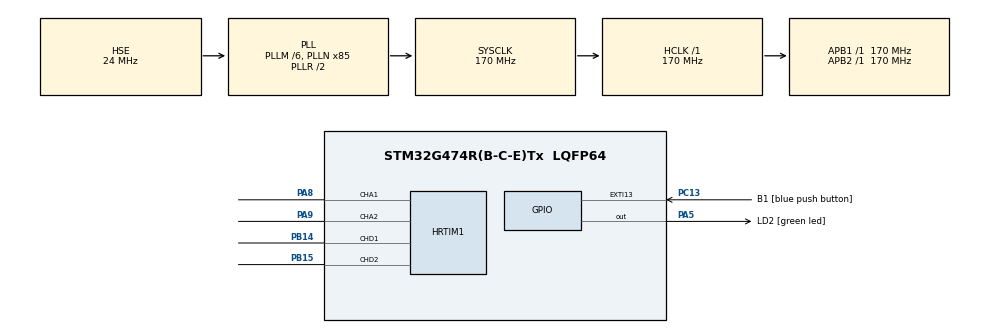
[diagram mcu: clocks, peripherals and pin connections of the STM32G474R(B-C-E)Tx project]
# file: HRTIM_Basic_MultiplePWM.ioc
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HRTIM1.ADCTrigger_Id1=__NULL
HRTIM1.ADCTrigger_Id10=__NULL
HRTIM1.ADCTrigger_Id2=__NULL
HRTIM1.ADCTrigger_Id3=__NULL
HRTIM1.ADCTrigger_Id4=__NULL
HRTIM1.ADCTrigger_Id5=__NULL
HRTIM1.ADCTrigger_Id6=__NULL
HRTIM1.ADCTrigger_Id7=__NULL
HRTIM1.ADCTrigger_Id8=__NULL
HRTIM1.ADCTrigger_Id9=__NULL
HRTIM1.AutoDelayedMode2-Output_TA1TA2=HRTIM_AUTODELAYEDMODE_REGULAR
HRTIM1.AutoDelayedMode2-Output_TD1TD2=HRTIM_AUTODELAYEDMODE_REGULAR
HRTIM1.BurstDMAconfig-Output_TA1TA2=__NULL
HRTIM1.BurstDMAconfig-Output_TD1TD2=__NULL
HRTIM1.BurstMode-Output_TA1TA2=HRTIM_TIMERBURSTMODE_MAINTAINCLOCK
HRTIM1.BurstMode-Output_TD1TD2=HRTIM_TIMERBURSTMODE_MAINTAINCLOCK
HRTIM1.BurstModeEntryDelayed1-Output_TA1TA2=HRTIM_OUTPUTBURSTMODEENTRY_REGULAR
HRTIM1.BurstModeEntryDelayed1-Output_TD1TD2=HRTIM_OUTPUTBURSTMODEENTRY_REGULAR
HRTIM1.BurstModeEntryDelayed2-Output_TA1TA2=HRTIM_OUTPUTBURSTMODEENTRY_REGULAR
HRTIM1.BurstModeEntryDelayed2-Output_TD1TD2=HRTIM_OUTPUTBURSTMODEENTRY_REGULAR
HRTIM1.CaptureUnit1-Output_TA1TA2=__NULL
HRTIM1.CaptureUnit1-Output_TD1TD2=__NULL
HRTIM1.CaptureUnit2-Output_TA1TA2=__NULL
HRTIM1.CaptureUnit2-Output_TD1TD2=__NULL
HRTIM1.ChopperModeEnable1-Output_TA1TA2=HRTIM_OUTPUTCHOPPERMODE_DISABLED
HRTIM1.ChopperModeEnable1-Output_TD1TD2=HRTIM_OUTPUTCHOPPERMODE_DISABLED
HRTIM1.ChopperModeEnable2-Output_TA1TA2=HRTIM_OUTPUTCHOPPERMODE_DISABLED
HRTIM1.ChopperModeEnable2-Output_TD1TD2=HRTIM_OUTPUTCHOPPERMODE_DISABLED
HRTIM1.ChopperModeconfig-Output_TA1TA2=__NULL
HRTIM1.ChopperModeconfig-Output_TD1TD2=__NULL
HRTIM1.CompareUnit1-Output_TA1TA2=HRTIM_COMPAREUNIT_1
HRTIM1.CompareUnit1-Output_TD1TD2=HRTIM_COMPAREUNIT_1
HRTIM1.CompareUnit2-Output_TA1TA2=HRTIM_COMPAREUNIT_2
HRTIM1.CompareUnit2-Output_TD1TD2=HRTIM_COMPAREUNIT_2
HRTIM1.CompareUnit3-Output_TA1TA2=HRTIM_COMPAREUNIT_3
HRTIM1.CompareUnit3-Output_TD1TD2=__NULL
HRTIM1.CompareUnit4-Output_TA1TA2=__NULL
HRTIM1.CompareUnit4-Output_TD1TD2=__NULL
HRTIM1.CompareValue1-Output_TA1TA2=TIMA_PERIOD/4
HRTIM1.CompareValue1-Output_TD1TD2=TIMD_PERIOD/4
HRTIM1.CompareValue2-Output_TA1TA2=TIMA_PERIOD/2
HRTIM1.CompareValue2-Output_TD1TD2=(3*TIMD_PERIOD)/4
HRTIM1.CompareValue3-Output_TA1TA2=(3*TIMA_PERIOD)/4
HRTIM1.Configuration_TA=Waveform
HRTIM1.Configuration_TD=Waveform
HRTIM1.DACSynchro-Output_TA1TA2=HRTIM_DACSYNC_NONE
HRTIM1.DACSynchro-Output_TD1TD2=HRTIM_DACSYNC_NONE
HRTIM1.DeadTimeInsertion-Output_TA1TA2=HRTIM_TIMDEADTIMEINSERTION_DISABLED
HRTIM1.DeadTimeInsertion-Output_TD1TD2=HRTIM_TIMDEADTIMEINSERTION_DISABLED
HRTIM1.Deadtimeconfig-Output_TA1TA2=__NULL
HRTIM1.Deadtimeconfig-Output_TD1TD2=__NULL
HRTIM1.DelayedProtectionMode-Output_TA1TA2=HRTIM_TIMER_A_B_C_DELAYEDPROTECTION_DISABLED
HRTIM1.DelayedProtectionMode-Output_TD1TD2=HRTIM_TIMER_D_E_DELAYEDPROTECTION_DISABLED
HRTIM1.DualChannelDacEnableFake_TA-Output_TA1TA2=HRTIM_TIMER_DCDE_DISABLED
HRTIM1.DualChannelDacEnableFake_TD-Output_TD1TD2=HRTIM_TIMER_DCDE_DISABLED
HRTIM1.Enable=HRTIM_BURSTMODECTL_DISABLED
HRTIM1.Event1-Output_TA1TA2=__NULL
HRTIM1.Event1-Output_TD1TD2=__NULL
HRTIM1.Event10-Output_TA1TA2=__NULL
HRTIM1.Event10-Output_TD1TD2=__NULL
HRTIM1.Event2-Output_TA1TA2=__NULL
HRTIM1.Event2-Output_TD1TD2=__NULL
HRTIM1.Event3-Output_TA1TA2=__NULL
HRTIM1.Event3-Output_TD1TD2=__NULL
HRTIM1.Event4-Output_TA1TA2=__NULL
HRTIM1.Event4-Output_TD1TD2=__NULL
HRTIM1.Event5-Output_TA1TA2=__NULL
HRTIM1.Event5-Output_TD1TD2=__NULL
HRTIM1.Event6-Output_TA1TA2=__NULL
HRTIM1.Event6-Output_TD1TD2=__NULL
HRTIM1.Event7-Output_TA1TA2=__NULL
HRTIM1.Event7-Output_TD1TD2=__NULL
HRTIM1.Event8-Output_TA1TA2=__NULL
HRTIM1.Event8-Output_TD1TD2=__NULL
HRTIM1.Event9-Output_TA1TA2=__NULL
HRTIM1.Event9-Output_TD1TD2=__NULL
HRTIM1.EventEnableA-Output_TA1TA2=__NULL
HRTIM1.EventEnableA-Output_TD1TD2=__NULL
HRTIM1.Event_EEV1=__NULL
HRTIM1.Event_EEV10=__NULL
HRTIM1.Event_EEV2=__NULL
HRTIM1.Event_EEV3=__NULL
HRTIM1.Event_EEV4=__NULL
HRTIM1.Event_EEV5=__NULL
HRTIM1.Event_EEV6=__NULL
HRTIM1.Event_EEV7=__NULL
HRTIM1.Event_EEV8=__NULL
HRTIM1.Event_EEV9=__NULL
HRTIM1.FaultLevel1-Output_TA1TA2=HRTIM_OUTPUTFAULTLEVEL_NONE
HRTIM1.FaultLevel1-Output_TD1TD2=HRTIM_OUTPUTFAULTLEVEL_NONE
HRTIM1.FaultLevel2-Output_TA1TA2=HRTIM_OUTPUTFAULTLEVEL_NONE
HRTIM1.FaultLevel2-Output_TD1TD2=HRTIM_OUTPUTFAULTLEVEL_NONE
HRTIM1.FaultLock-Output_TA1TA2=HRTIM_TIMFAULTLOCK_READWRITE
HRTIM1.FaultLock-Output_TD1TD2=HRTIM_TIMFAULTLOCK_READWRITE
HRTIM1.Fault_Line1=__NULL
HRTIM1.Fault_Line2=__NULL
HRTIM1.Fault_Line3=__NULL
HRTIM1.Fault_Line4=__NULL
HRTIM1.Fault_Line5=__NULL
HRTIM1.Fault_Line6=__NULL
HRTIM1.GreaterCMP1_TA=HRTIM_TIMERGTCMP1_GREATER
HRTIM1.GreaterCMP1_TD=HRTIM_TIMERGTCMP1_EQUAL
HRTIM1.GreaterCMP3_TA=HRTIM_TIMERGTCMP3_EQUAL
HRTIM1.HRTIMInterruptResquests1=HRTIM_IT_NONE
HRTIM1.HRTIMInterruptResquests2=HRTIM_IT_NONE
HRTIM1.HRTIMInterruptResquests3=HRTIM_IT_NONE
HRTIM1.HRTIMInterruptResquests4=HRTIM_IT_NONE
HRTIM1.HRTIMInterruptResquests5=HRTIM_IT_NONE
HRTIM1.HRTIMInterruptResquests6=HRTIM_IT_NONE
HRTIM1.HRTIMInterruptResquests7=HRTIM_IT_NONE
HRTIM1.HRTIMInterruptResquests8=HRTIM_IT_NONE
HRTIM1.HRTIMInterruptResquests9=HRTIM_IT_NONE
HRTIM1.IdleLevel1-Output_TA1TA2=HRTIM_OUTPUTIDLELEVEL_INACTIVE
HRTIM1.IdleLevel1-Output_TD1TD2=HRTIM_OUTPUTIDLELEVEL_INACTIVE
HRTIM1.IdleLevel2-Output_TA1TA2=HRTIM_OUTPUTIDLELEVEL_INACTIVE
HRTIM1.IdleLevel2-Output_TD1TD2=HRTIM_OUTPUTIDLELEVEL_INACTIVE
HRTIM1.IdleMode1-Output_TA1TA2=HRTIM_OUTPUTIDLEMODE_NONE
HRTIM1.IdleMode1-Output_TD1TD2=HRTIM_OUTPUTIDLEMODE_NONE
HRTIM1.IdleMode2-Output_TA1TA2=HRTIM_OUTPUTIDLEMODE_NONE
HRTIM1.IdleMode2-Output_TD1TD2=HRTIM_OUTPUTIDLEMODE_NONE
HRTIM1.InterleavedMode-Output_TA1TA2=HRTIM_INTERLEAVED_MODE_DISABLED
HRTIM1.InterleavedMode-Output_TD1TD2=HRTIM_INTERLEAVED_MODE_DISABLED
HRTIM1.ModeTimeBase-Output_TA1TA2=HRTIM_MODE_CONTINUOUS
HRTIM1.ModeTimeBase-Output_TD1TD2=HRTIM_MODE_CONTINUOUS
HRTIM1.NumberDMARequests_TA=0
HRTIM1.NumberDMARequests_TD=0
HRTIM1.NumberFaultEnable-Output_TA1TA2=0
HRTIM1.NumberFaultEnable-Output_TD1TD2=0
HRTIM1.NumberInterruptRequests-Output_TA1TA2=0
HRTIM1.NumberInterruptRequests-Output_TD1TD2=0
HRTIM1.NumberResetSource1-Output_TA1TA2=1
HRTIM1.NumberResetSource1-Output_TD1TD2=1
HRTIM1.NumberResetSource2_TA=1
HRTIM1.NumberResetSource2_TD=1
HRTIM1.NumberResetTrigger-Output_TA1TA2=0
HRTIM1.NumberResetTrigger-Output_TD1TD2=0
HRTIM1.NumberSetSource1-Output_TA1TA2=1
HRTIM1.NumberSetSource1-Output_TD1TD2=1
HRTIM1.NumberSetSource2_TA=1
HRTIM1.NumberSetSource2_TD=1
HRTIM1.NumberUpdateTrigger-Output_TA1TA2=0
HRTIM1.NumberUpdateTrigger-Output_TD1TD2=0
HRTIM1.Output1-Output_TA1TA2=HRTIM_OUTPUT_TA1
HRTIM1.Output1-Output_TD1TD2=HRTIM_OUTPUT_TD1
HRTIM1.Output2-Output_TA1TA2=HRTIM_OUTPUT_TA2
HRTIM1.Output2-Output_TD1TD2=HRTIM_OUTPUT_TD2
HRTIM1.Periode_TA=TIMA_PERIOD
HRTIM1.Periode_TD=TIMD_PERIOD
HRTIM1.Polarity1-Output_TA1TA2=HRTIM_OUTPUTPOLARITY_HIGH
HRTIM1.Polarity1-Output_TD1TD2=HRTIM_OUTPUTPOLARITY_HIGH
HRTIM1.Polarity2-Output_TA1TA2=HRTIM_OUTPUTPOLARITY_HIGH
HRTIM1.Polarity2-Output_TD1TD2=HRTIM_OUTPUTPOLARITY_HIGH
HRTIM1.PreloadEnable-Output_TA1TA2=HRTIM_PRELOAD_DISABLED
HRTIM1.PreloadEnable-Output_TD1TD2=HRTIM_PRELOAD_DISABLED
HRTIM1.PushPull-Output_TA1TA2=HRTIM_TIMPUSHPULLMODE_DISABLED
HRTIM1.PushPull-Output_TD1TD2=HRTIM_TIMPUSHPULLMODE_DISABLED
HRTIM1.ReSyncUpdate-Output_TA1TA2=HRTIM_TIMERESYNC_UPDATE_UNCONDITIONAL
HRTIM1.ReSyncUpdate-Output_TD1TD2=HRTIM_TIMERESYNC_UPDATE_UNCONDITIONAL
HRTIM1.RepetitionUpdate-Output_TA1TA2=HRTIM_UPDATEONREPETITION_DISABLED
HRTIM1.RepetitionUpdate-Output_TD1TD2=HRTIM_UPDATEONREPETITION_DISABLED
HRTIM1.ResetOnSync-Output_TA1TA2=HRTIM_SYNCRESET_DISABLED
HRTIM1.ResetOnSync-Output_TD1TD2=HRTIM_SYNCRESET_DISABLED
HRTIM1.ResetOutput1_Source1-Output_TA1TA2=HRTIM_OUTPUTRESET_TIMCMP1
HRTIM1.ResetOutput1_Source1-Output_TD1TD2=HRTIM_OUTPUTRESET_TIMCMP1
HRTIM1.ResetOutput2_Source1-Output_TA1TA2=HRTIM_OUTPUTRESET_TIMCMP3
HRTIM1.ResetOutput2_Source1-Output_TD1TD2=HRTIM_OUTPUTRESET_TIMPER
HRTIM1.ResetUpdate-Output_TA1TA2=HRTIM_TIMUPDATEONRESET_DISABLED
HRTIM1.ResetUpdate-Output_TD1TD2=HRTIM_TIMUPDATEONRESET_DISABLED
HRTIM1.SetOutput1_Source1-Output_TA1TA2=HRTIM_OUTPUTSET_TIMPER
HRTIM1.SetOutput1_Source1-Output_TD1TD2=HRTIM_OUTPUTSET_TIMPER
HRTIM1.SetOutput2_Source1-Output_TA1TA2=HRTIM_OUTPUTSET_TIMCMP2
HRTIM1.SetOutput2_Source1-Output_TD1TD2=HRTIM_OUTPUTSET_TIMCMP2
HRTIM1.StartOnSync-Output_TA1TA2=HRTIM_SYNCSTART_DISABLED
HRTIM1.StartOnSync-Output_TD1TD2=HRTIM_SYNCSTART_DISABLED
HRTIM1.SwapA=__NULL
HRTIM1.SwapD=__NULL
HRTIM1.SyncOptions=HRTIM_SYNCOPTION_NONE
HRTIM1.TimerIdx-Output_TA1TA2=HRTIM_TIMERINDEX_TIMER_A
HRTIM1.TimerIdx-Output_TD1TD2=HRTIM_TIMERINDEX_TIMER_D
HRTIM1.TrigHalf_TA=HRTIM_TIMERTRIGHALF_DISABLED
HRTIM1.TrigHalf_TD=HRTIM_TIMERTRIGHALF_DISABLED
HRTIM1.UpDownMode-Output_TA1TA2=HRTIM_TIMERUPDOWNMODE_UP
HRTIM1.UpDownMode-Output_TD1TD2=HRTIM_TIMERUPDOWNMODE_UP
HRTIM1.UpdateGating-Output_TA1TA2=HRTIM_UPDATEGATING_INDEPENDENT
HRTIM1.UpdateGating-Output_TD1TD2=HRTIM_UPDATEGATING_INDEPENDENT
Mcu.Family=STM32G4
Mcu.Name=STM32G474R(B-C-E)Tx
Mcu.Package=LQFP64
Mcu.UserConstants=HRTIM_INPUT_CLOCK,170000000;TIMA_PWM_FREQ,100000
NVIC.EXTI15_10_IRQn=true\:0\:0\:false\:false\:true\:true\:true\:true
NVIC.PriorityGroup=NVIC_PRIORITYGROUP_4
PA13.GPIO_Label=T_SWDIO
PA13.Mode=Serial_Wire
PA13.Signal=SYS_JTMS-SWDIO
PA14.GPIO_Label=T_SWCLK
PA14.Mode=Serial_Wire
PA14.Signal=SYS_JTCK-SWCLK
PA5.GPIO_Label=LD2 [green led]
PA5.Signal=GPIO_Output
PA8.Mode=Output_TA1TA2
PA8.Signal=HRTIM1_CHA1
PA9.Mode=Output_TA1TA2
PA9.Signal=HRTIM1_CHA2
PB14.Mode=Output_TD1TD2
PB14.Signal=HRTIM1_CHD1
PB15.Mode=Output_TD1TD2
PB15.Signal=HRTIM1_CHD2
PB3.GPIO_Label=T_SWO
PB3.Signal=SYS_JTDO-SWO
PC13.GPIO_Label=B1 [blue push button]
PC13.Signal=GPXTI13
PC14-OSC32_IN.Signal=RCC_OSC32_IN
PC15-OSC32_OUT.Signal=RCC_OSC32_OUT
PC4.GPIO_Label=USART1_TX [STLINKV3E_VCP_RX]
PC4.Signal=USART1_TX
PC5.GPIO_Label=USART1_RX [STLINKV3E_VCP_TX]
PC5.Signal=USART1_RX
PF0-OSC_IN.Mode=HSE-External-Oscillator
PF0-OSC_IN.Signal=RCC_OSC_IN
PF1-OSC_OUT.Mode=HSE-External-Oscillator
PF1-OSC_OUT.Signal=RCC_OSC_OUT
ProjectManager.HeapSize=0x200
ProjectManager.StackSize=0x400
ProjectManager.TargetToolchain=MDK-ARM V5.32
RCC.ADC12Freq_Value=170000000
RCC.ADC345Freq_Value=170000000
RCC.AHBFreq_Value=170000000
RCC.APB1Freq_Value=170000000
RCC.APB1TimFreq_Value=170000000
RCC.APB2Freq_Value=170000000
RCC.APB2TimFreq_Value=170000000
RCC.CortexFreq_Value=170000000
RCC.EXTERNAL_CLOCK_VALUE=12288000
RCC.HCLKFreq_Value=170000000
RCC.HSE_VALUE=24000000
RCC.HSI48_VALUE=48000000
RCC.HSI_VALUE=16000000
RCC.LSE_VALUE=32768
RCC.PLLM=RCC_PLLM_DIV6
RCC.PLLN=85
RCC.PLLSourceVirtual=RCC_PLLSOURCE_HSE
RCC.SYSCLKFreq_VALUE=170000000
RCC.SYSCLKSource=RCC_SYSCLKSOURCE_PLLCLK
RCC.USBFreq_Value=170000000
RCC.VCOOutputFreq_Value=340000000
VP_SYS_VS_DBSignals.Mode=DisableDeadBatterySignals
board=custom

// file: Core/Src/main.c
/* USER CODE BEGIN Header */
/**
  ******************************************************************************
  * @file    Examples/HRTIM/HRTIM_Basic_MultiplePWM/Src/main.c
  * @author  MCD Application Team
  * @brief   This example describes how to configure and use HRTIM through
  *          the STM32G4xx HAL API.
  ******************************************************************************
  * @attention
  *
  * Copyright (c) 2019-2021 STMicroelectronics.
  * All rights reserved.
  *
  * This software is licensed under terms that can be found in the LICENSE file
  * in the root directory of this software component.
  * If no LICENSE file comes with this software, it is provided AS-IS.
  *
  ******************************************************************************
  */
/* USER CODE END Header */
#include "main.h"

/* USER CODE BEGIN Includes */
#include "STM32G4xx_BORING.h"
/* USER CODE END Includes */

/* USER CODE BEGIN PD */

#define TIMD_PWM_FREQ (uint32_t)(TIMA_PWM_FREQ/3)

/* Formula below works for PWM frequency > 83kHz (with prescaler ratio = 1) */
#define TIMA_PERIOD ((uint16_t)(((uint64_t)HRTIM_INPUT_CLOCK * 32) / TIMA_PWM_FREQ))

/* Formula below works for PWM frequency > 20.8kHz (with prescaler ratio = 4) */
#define TIMD_PERIOD ((uint16_t)(((uint64_t)HRTIM_INPUT_CLOCK * 8) / TIMD_PWM_FREQ))

/* USER CODE END PD */

HRTIM_HandleTypeDef hhrtim1;

void SystemClock_Config(void);
static void MX_GPIO_Init(void);
static void MX_HRTIM1_Init(void);

int main(void)
{

  /* MCU Configuration--------------------------------------------------------*/

  /* Reset of all peripherals, Initializes the Flash interface and the Systick. */
  HAL_Init();

  /* Configure the system clock */
  SystemClock_Config();

  /* Initialize all configured peripherals */
  MX_GPIO_Init();
  MX_HRTIM1_Init();
  /* USER CODE BEGIN 2 */

  /* LED_RED toggles during the demo */
  BSP_LED_Init(LED_RED);

  /* Enable HRTIM's outputs TA1, TA2, TD1 and TD2 and start timers A and D */
  HAL_HRTIM_WaveformOutputStart(&hhrtim1, HRTIM_OUTPUT_TA1 + HRTIM_OUTPUT_TA2
                                       + HRTIM_OUTPUT_TD1 + HRTIM_OUTPUT_TD2);
  HAL_HRTIM_WaveformCounterStart(&hhrtim1, HRTIM_TIMERID_TIMER_A + HRTIM_TIMERID_TIMER_D);

  /* USER CODE END 2 */

  /* Infinite loop */
  while (1)
  {

    /* USER CODE BEGIN 3 */

    BSP_LED_Toggle(LED_RED);
    HAL_Delay(100);

  }
  /* USER CODE END 3 */
}

void SystemClock_Config(void)
{
  RCC_OscInitTypeDef RCC_OscInitStruct = {0};
  RCC_ClkInitTypeDef RCC_ClkInitStruct = {0};

  /** Configure the main internal regulator output voltage
  */
  HAL_PWREx_ControlVoltageScaling(PWR_REGULATOR_VOLTAGE_SCALE1_BOOST);

  /** Initializes the RCC Oscillators according to the specified parameters
  * in the RCC_OscInitTypeDef structure.
  */
  RCC_OscInitStruct.OscillatorType = RCC_OSCILLATORTYPE_HSE;
  RCC_OscInitStruct.HSEState = RCC_HSE_ON;
  RCC_OscInitStruct.PLL.PLLState = RCC_PLL_ON;
  RCC_OscInitStruct.PLL.PLLSource = RCC_PLLSOURCE_HSE;
  RCC_OscInitStruct.PLL.PLLM = RCC_PLLM_DIV6;
  RCC_OscInitStruct.PLL.PLLN = 85;
  RCC_OscInitStruct.PLL.PLLP = RCC_PLLP_DIV2;
  RCC_OscInitStruct.PLL.PLLQ = RCC_PLLQ_DIV2;
  RCC_OscInitStruct.PLL.PLLR = RCC_PLLR_DIV2;
  if (HAL_RCC_OscConfig(&RCC_OscInitStruct) != HAL_OK)
  {
    Error_Handler();
  }

  /** Initializes the CPU, AHB and APB buses clocks
  */
  RCC_ClkInitStruct.ClockType = RCC_CLOCKTYPE_HCLK|RCC_CLOCKTYPE_SYSCLK
                              |RCC_CLOCKTYPE_PCLK1|RCC_CLOCKTYPE_PCLK2;
  RCC_ClkInitStruct.SYSCLKSource = RCC_SYSCLKSOURCE_PLLCLK;
  RCC_ClkInitStruct.AHBCLKDivider = RCC_SYSCLK_DIV1;
  RCC_ClkInitStruct.APB1CLKDivider = RCC_HCLK_DIV1;
  RCC_ClkInitStruct.APB2CLKDivider = RCC_HCLK_DIV1;

  if (HAL_RCC_ClockConfig(&RCC_ClkInitStruct, FLASH_LATENCY_4) != HAL_OK)
  {
    Error_Handler();
  }
}

static void MX_HRTIM1_Init(void)
{

  HRTIM_TimeBaseCfgTypeDef pTimeBaseCfg = {0};
  HRTIM_TimerCtlTypeDef pTimerCtl = {0};
  HRTIM_TimerCfgTypeDef pTimerCfg = {0};
  HRTIM_CompareCfgTypeDef pCompareCfg = {0};
  HRTIM_OutputCfgTypeDef pOutputCfg = {0};

  hhrtim1.Instance = HRTIM1;
  hhrtim1.Init.HRTIMInterruptResquests = HRTIM_IT_NONE;
  hhrtim1.Init.SyncOptions = HRTIM_SYNCOPTION_NONE;
  if (HAL_HRTIM_Init(&hhrtim1) != HAL_OK)
  {
    Error_Handler();
  }
  if (HAL_HRTIM_DLLCalibrationStart(&hhrtim1, HRTIM_CALIBRATIONRATE_3) != HAL_OK)
  {
    Error_Handler();
  }
  if (HAL_HRTIM_PollForDLLCalibration(&hhrtim1, 10) != HAL_OK)
  {
    Error_Handler();
  }
  pTimeBaseCfg.Period = TIMA_PERIOD;
  pTimeBaseCfg.RepetitionCounter = 0x00;
  pTimeBaseCfg.PrescalerRatio = HRTIM_PRESCALERRATIO_MUL32;
  pTimeBaseCfg.Mode = HRTIM_MODE_CONTINUOUS;
  if (HAL_HRTIM_TimeBaseConfig(&hhrtim1, HRTIM_TIMERINDEX_TIMER_A, &pTimeBaseCfg) != HAL_OK)
  {
    Error_Handler();
  }
  pTimerCtl.UpDownMode = HRTIM_TIMERUPDOWNMODE_UP;
  pTimerCtl.TrigHalf = HRTIM_TIMERTRIGHALF_DISABLED;
  pTimerCtl.GreaterCMP3 = HRTIM_TIMERGTCMP3_EQUAL;
  pTimerCtl.GreaterCMP1 = HRTIM_TIMERGTCMP1_GREATER;
  pTimerCtl.DualChannelDacEnable = HRTIM_TIMER_DCDE_DISABLED;
  if (HAL_HRTIM_WaveformTimerControl(&hhrtim1, HRTIM_TIMERINDEX_TIMER_A, &pTimerCtl) != HAL_OK)
  {
    Error_Handler();
  }
  pTimerCfg.InterruptRequests = HRTIM_TIM_IT_NONE;
  pTimerCfg.DMARequests = HRTIM_TIM_DMA_NONE;
  pTimerCfg.DMASrcAddress = 0x0000;
  pTimerCfg.DMADstAddress = 0x0000;
  pTimerCfg.DMASize = 0x1;
  pTimerCfg.HalfModeEnable = HRTIM_HALFMODE_DISABLED;
  pTimerCfg.InterleavedMode = HRTIM_INTERLEAVED_MODE_DISABLED;
  pTimerCfg.StartOnSync = HRTIM_SYNCSTART_DISABLED;
  pTimerCfg.ResetOnSync = HRTIM_SYNCRESET_DISABLED;
  pTimerCfg.DACSynchro = HRTIM_DACSYNC_NONE;
  pTimerCfg.PreloadEnable = HRTIM_PRELOAD_DISABLED;
  pTimerCfg.UpdateGating = HRTIM_UPDATEGATING_INDEPENDENT;
  pTimerCfg.BurstMode = HRTIM_TIMERBURSTMODE_MAINTAINCLOCK;
  pTimerCfg.RepetitionUpdate = HRTIM_UPDATEONREPETITION_DISABLED;
  pTimerCfg.PushPull = HRTIM_TIMPUSHPULLMODE_DISABLED;
  pTimerCfg.FaultEnable = HRTIM_TIMFAULTENABLE_NONE;
  pTimerCfg.FaultLock = HRTIM_TIMFAULTLOCK_READWRITE;
  pTimerCfg.DeadTimeInsertion = HRTIM_TIMDEADTIMEINSERTION_DISABLED;
  pTimerCfg.DelayedProtectionMode = HRTIM_TIMER_A_B_C_DELAYEDPROTECTION_DISABLED;
  pTimerCfg.UpdateTrigger = HRTIM_TIMUPDATETRIGGER_NONE;
  pTimerCfg.ResetTrigger = HRTIM_TIMRESETTRIGGER_NONE;
  pTimerCfg.ResetUpdate = HRTIM_TIMUPDATEONRESET_DISABLED;
  pTimerCfg.ReSyncUpdate = HRTIM_TIMERESYNC_UPDATE_UNCONDITIONAL;
  if (HAL_HRTIM_WaveformTimerConfig(&hhrtim1, HRTIM_TIMERINDEX_TIMER_A, &pTimerCfg) != HAL_OK)
  {
    Error_Handler();
  }
  pTimerCfg.DelayedProtectionMode = HRTIM_TIMER_D_E_DELAYEDPROTECTION_DISABLED;
  if (HAL_HRTIM_WaveformTimerConfig(&hhrtim1, HRTIM_TIMERINDEX_TIMER_D, &pTimerCfg) != HAL_OK)
  {
    Error_Handler();
  }
  pCompareCfg.CompareValue = TIMA_PERIOD/4;
  if (HAL_HRTIM_WaveformCompareConfig(&hhrtim1, HRTIM_TIMERINDEX_TIMER_A, HRTIM_COMPAREUNIT_1, &pCompareCfg) != HAL_OK)
  {
    Error_Handler();
  }
  pCompareCfg.CompareValue = TIMA_PERIOD/2;
  pCompareCfg.AutoDelayedMode = HRTIM_AUTODELAYEDMODE_REGULAR;
  pCompareCfg.AutoDelayedTimeout = 0x0000;

  if (HAL_HRTIM_WaveformCompareConfig(&hhrtim1, HRTIM_TIMERINDEX_TIMER_A, HRTIM_COMPAREUNIT_2, &pCompareCfg) != HAL_OK)
  {
    Error_Handler();
  }
  pCompareCfg.CompareValue = (3*TIMA_PERIOD)/4;
  if (HAL_HRTIM_WaveformCompareConfig(&hhrtim1, HRTIM_TIMERINDEX_TIMER_A, HRTIM_COMPAREUNIT_3, &pCompareCfg) != HAL_OK)
  {
    Error_Handler();
  }
  pOutputCfg.Polarity = HRTIM_OUTPUTPOLARITY_HIGH;
  pOutputCfg.SetSource = HRTIM_OUTPUTSET_TIMPER;
  pOutputCfg.ResetSource = HRTIM_OUTPUTRESET_TIMCMP1;
  pOutputCfg.IdleMode = HRTIM_OUTPUTIDLEMODE_NONE;
  pOutputCfg.IdleLevel = HRTIM_OUTPUTIDLELEVEL_INACTIVE;
  pOutputCfg.FaultLevel = HRTIM_OUTPUTFAULTLEVEL_NONE;
  pOutputCfg.ChopperModeEnable = HRTIM_OUTPUTCHOPPERMODE_DISABLED;
  pOutputCfg.BurstModeEntryDelayed = HRTIM_OUTPUTBURSTMODEENTRY_REGULAR;
  if (HAL_HRTIM_WaveformOutputConfig(&hhrtim1, HRTIM_TIMERINDEX_TIMER_A, HRTIM_OUTPUT_TA1, &pOutputCfg) != HAL_OK)
  {
    Error_Handler();
  }
  if (HAL_HRTIM_WaveformOutputConfig(&hhrtim1, HRTIM_TIMERINDEX_TIMER_D, HRTIM_OUTPUT_TD1, &pOutputCfg) != HAL_OK)
  {
    Error_Handler();
  }
  pOutputCfg.SetSource = HRTIM_OUTPUTSET_TIMCMP2;
  pOutputCfg.ResetSource = HRTIM_OUTPUTRESET_TIMCMP3;
  if (HAL_HRTIM_WaveformOutputConfig(&hhrtim1, HRTIM_TIMERINDEX_TIMER_A, HRTIM_OUTPUT_TA2, &pOutputCfg) != HAL_OK)
  {
    Error_Handler();
  }
  pOutputCfg.ResetSource = HRTIM_OUTPUTRESET_TIMPER;
  if (HAL_HRTIM_WaveformOutputConfig(&hhrtim1, HRTIM_TIMERINDEX_TIMER_D, HRTIM_OUTPUT_TD2, &pOutputCfg) != HAL_OK)
  {
    Error_Handler();
  }
  pTimeBaseCfg.Period = TIMD_PERIOD;
  if (HAL_HRTIM_TimeBaseConfig(&hhrtim1, HRTIM_TIMERINDEX_TIMER_D, &pTimeBaseCfg) != HAL_OK)
  {
    Error_Handler();
  }
  pTimerCtl.GreaterCMP1 = HRTIM_TIMERGTCMP1_EQUAL;
  if (HAL_HRTIM_WaveformTimerControl(&hhrtim1, HRTIM_TIMERINDEX_TIMER_D, &pTimerCtl) != HAL_OK)
  {
    Error_Handler();
  }
  pCompareCfg.CompareValue = TIMD_PERIOD/4;
  if (HAL_HRTIM_WaveformCompareConfig(&hhrtim1, HRTIM_TIMERINDEX_TIMER_D, HRTIM_COMPAREUNIT_1, &pCompareCfg) != HAL_OK)
  {
    Error_Handler();
  }
  pCompareCfg.CompareValue = (3*TIMD_PERIOD)/4;

  if (HAL_HRTIM_WaveformCompareConfig(&hhrtim1, HRTIM_TIMERINDEX_TIMER_D, HRTIM_COMPAREUNIT_2, &pCompareCfg) != HAL_OK)
  {
    Error_Handler();
  }
  HAL_HRTIM_MspPostInit(&hhrtim1);

}

static void MX_GPIO_Init(void)
{
  GPIO_InitTypeDef GPIO_InitStruct = {0};

  /* GPIO Ports Clock Enable */
  __HAL_RCC_GPIOC_CLK_ENABLE();
  __HAL_RCC_GPIOF_CLK_ENABLE();
  __HAL_RCC_GPIOA_CLK_ENABLE();
  __HAL_RCC_GPIOB_CLK_ENABLE();

  /*Configure GPIO pin Output Level */
  HAL_GPIO_WritePin(LD2_GPIO_Port, LD2_Pin, GPIO_PIN_RESET);

  /*Configure GPIO pin : B1_Pin */
  GPIO_InitStruct.Pin = B1_Pin;
  GPIO_InitStruct.Mode = GPIO_MODE_IT_RISING;
  GPIO_InitStruct.Pull = GPIO_NOPULL;
  HAL_GPIO_Init(B1_GPIO_Port, &GPIO_InitStruct);

  /*Configure GPIO pin : LD2_Pin */
  GPIO_InitStruct.Pin = LD2_Pin;
  GPIO_InitStruct.Mode = GPIO_MODE_OUTPUT_PP;
  GPIO_InitStruct.Pull = GPIO_NOPULL;
  GPIO_InitStruct.Speed = GPIO_SPEED_FREQ_LOW;
  HAL_GPIO_Init(LD2_GPIO_Port, &GPIO_InitStruct);

  /*Configure GPIO pins : USART1_TX_Pin USART1_RX_Pin */
  GPIO_InitStruct.Pin = USART1_TX_Pin|USART1_RX_Pin;
  GPIO_InitStruct.Mode = GPIO_MODE_AF_PP;
  GPIO_InitStruct.Pull = GPIO_NOPULL;
  GPIO_InitStruct.Speed = GPIO_SPEED_FREQ_LOW;
  GPIO_InitStruct.Alternate = GPIO_AF7_USART1;
  HAL_GPIO_Init(GPIOC, &GPIO_InitStruct);

  /* EXTI interrupt init*/
  HAL_NVIC_SetPriority(EXTI15_10_IRQn, 0, 0);
  HAL_NVIC_EnableIRQ(EXTI15_10_IRQn);

}

void Error_Handler(void)
{
  /* USER CODE BEGIN Error_Handler_Debug */

  /* Turn LED_RED (GREEN) on */
  BSP_LED_On(LED_RED);
  /* User can add his own implementation to report the HAL error return state */
  while(1)
  {
  }
  /* USER CODE END Error_Handler_Debug */
}
